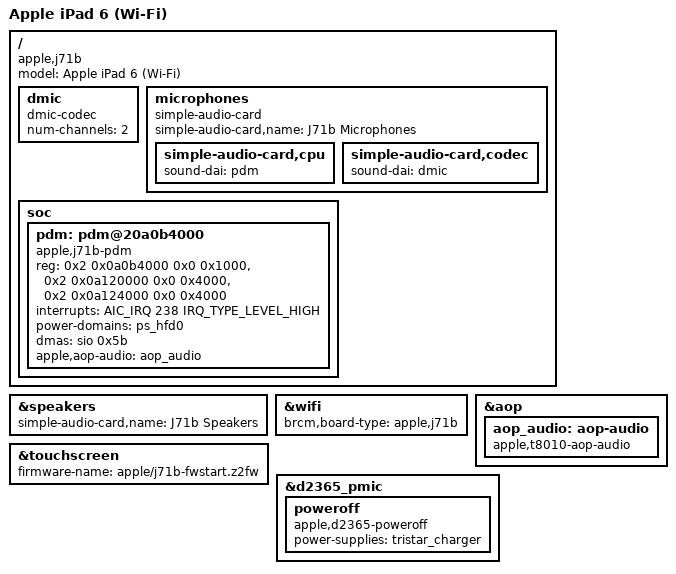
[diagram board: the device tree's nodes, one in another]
// SPDX-License-Identifier: GPL-2.0+ OR MIT
/*
 * Apple iPad 6 (Wi-Fi), J71b, iPad7,5 (A1893)
 * Copyright (c) 2022, Konrad Dybcio <konradybcio@kernel.org>
 */

/* Experimental capture: assumes one Linux host HP requester. */
/dts-v1/;

#include "t8010-ipad6.dtsi"

/ {
	compatible = "apple,j71b", "apple,t8010", "apple,arm-platform";
	model = "Apple iPad 6 (Wi-Fi)";

	dmic: dmic {
		compatible = "dmic-codec";
		#sound-dai-cells = <0>;
		num-channels = <2>;
		status = "okay";
	};

	microphones {
		compatible = "simple-audio-card";
		simple-audio-card,name = "J71b Microphones";
		status = "okay";

		simple-audio-card,cpu {
			sound-dai = <&pdm>;
		};

		simple-audio-card,codec {
			sound-dai = <&dmic>;
		};
	};

	soc {
		pdm: pdm@20a0b4000 {
			compatible = "apple,j71b-pdm";
			reg = <0x2 0x0a0b4000 0x0 0x1000>,
			      <0x2 0x0a120000 0x0 0x4000>,
			      <0x2 0x0a124000 0x0 0x4000>;
			reg-names = "pdmc", "decimator0", "decimator1";
			interrupts = <AIC_IRQ 238 IRQ_TYPE_LEVEL_HIGH>;
			power-domains = <&ps_hfd0>;
			dmas = <&sio 0x5b>;
			dma-names = "rx";
			apple,aop-audio = <&aop_audio>;
			#sound-dai-cells = <0>;
			status = "okay";
		};
	};

};

&speakers {
	simple-audio-card,name = "J71b Speakers";
};

&wifi {
	brcm,board-type = "apple,j71b";
};

&aop {
	aop_audio: aop-audio {
		compatible = "apple,t8010-aop-audio";
		status = "okay";
	};
};

&touchscreen {
	firmware-name = "apple/j71b-fwstart.z2fw";
};

&d2365_pmic {
	poweroff {
		compatible = "apple,d2365-poweroff";
		power-supplies = <&tristar_charger>;
	};
};
